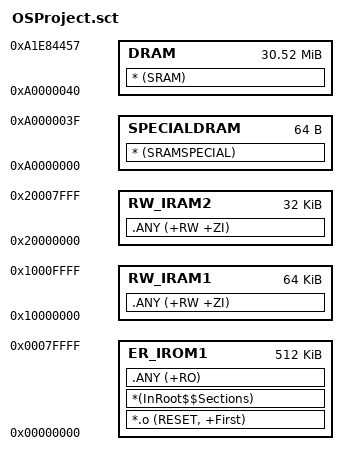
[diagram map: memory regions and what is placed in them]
; *************************************************************
; *** Scatter-Loading Description File generated by uVision ***
; *************************************************************
;
;  //SCB->VTOR  = 0x00020000 & 0x3FFFFF80;   // Have BOOTLOAD //
;  //SCB->VTOR  = 0x00000000 & 0x3FFFFF80;   // None BOOTLOAD SETTING //
;
;LR_IROM1 0x00020000 0x00080000  {    ; load region size_region            // Have BOOTLOAD //
;  ER_IROM1 0x00020000 0x00080000  {  ; load address = execution address   // Have BOOTLOAD //
;
LR_IROM1 0x00000000 0x00080000  {    ; load region size_region             // None BOOTLOAD SETTING //
  ER_IROM1 0x00000000 0x00080000  {  ; load address = execution address    // None BOOTLOAD SETTING //
   *.o (RESET, +First)
   *(InRoot$$Sections)
   .ANY (+RO)
  }
  RW_IRAM1 0x10000000 0x00010000  {
   .ANY (+RW +ZI)
  }
  RW_IRAM2 0x20000000 0x00008000  {
   .ANY (+RW +ZI)
  }
  ;RW_IRAM3 0x20084000 UNINIT 0x20087FFF    ; RW data
  ;  LPC17_EMAC.o (+ZI +RW)
  ;
  SPECIALDRAM   0XA0000000  0x00000040
 {
   * (SRAMSPECIAL)
 }
  DRAM   0XA0000040  0x01E84418
 {
   * (SRAM)
 }
}

